AUTOSAR XML (schema 4-2-2)
package /ComponentTypes
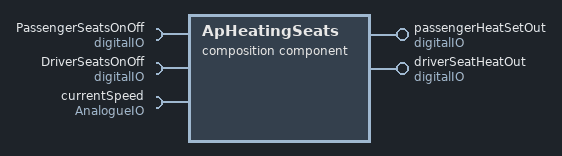
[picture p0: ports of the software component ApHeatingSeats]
  composition sw component type ApHeatingSeats
    require port PassengerSeatsOnOff: required-interface=digitalIO
    require port DriverSeatsOnOff: required-interface=digitalIO
    provide port passengerHeatSetOut: provided-interface=digitalIO
    provide port driverSeatHeatOut: provided-interface=digitalIO
    require port currentSpeed: nonqueued-receiver-com-spec=data-element=speed, required-interface=AnalogueIO
    component HeatedSeatsDriverCtrl: type=SeatController
    component HeatedSeatsPassengerCtrl: type=SeatController
    delegate HeatedSeatsDriverCtrl.SeatsOnOff <-> outer port PassengerSeatsOnOff
    delegate HeatedSeatsDriverCtrl.heatedSeatsOnOff <-> outer port passengerHeatSetOut
    delegate HeatedSeatsPassengerCtrl.SeatsOnOff <-> outer port DriverSeatsOnOff
    delegate HeatedSeatsPassengerCtrl.heatedSeatsOnOff <-> outer port driverSeatHeatOut
    delegate HeatedSeatsDriverCtrl.speedIn <-> outer port currentSpeed
    delegate HeatedSeatsPassengerCtrl.speedIn <-> outer port currentSpeed
